# MKL05Z4 register map
Vendor: Freescale Semiconductor, Inc.; File version: 1.6
CPU: CM0PLUS r0p0, little endian, no MPU, no FPU, 0x2 interrupt priority bits, 0x0 interrupts
Registers are 32-bit, read-write, reset 0x0 unless marked. A register's access mark holds for its fields unless they carry their own. Offsets are from the block's base; [hi:lo] are bit positions; {n}, {i} and the like mark numbered series.

## GPIOA — General Purpose Input/Output
Base 0x400FF000; register names take the prefix GPIOA_
0x00 PDOR — Port Data Output Register
  [31:0] PDO — Port Data Output
    0=Logic level 0 is driven on pin, provided pin is configured for general-purpose output; 1=Logic level 1 is driven on pin, provided pin is configured for general-purpose output
0x04 PSOR wo — Port Set Output Register
  [31:0] PTSO — Port Set Output
    0=Corresponding bit in PDORn does not change; 1=Corresponding bit in PDORn is set to logic 1
0x08 PCOR wo — Port Clear Output Register
  [31:0] PTCO — Port Clear Output
    0=Corresponding bit in PDORn does not change; 1=Corresponding bit in PDORn is cleared to logic 0
0x0C PTOR wo — Port Toggle Output Register
  [31:0] PTTO — Port Toggle Output
    0=Corresponding bit in PDORn does not change; 1=Corresponding bit in PDORn is set to the inverse of its existing logic state
0x10 PDIR ro — Port Data Input Register
  [31:0] PDI — Port Data Input
    0=Pin logic level is logic 0, or is not configured for use by digital function; 1=Pin logic level is logic 1
0x14 PDDR — Port Data Direction Register
  [31:0] PDD — Port Data Direction
    0=Pin is configured as general-purpose input, for the GPIO function; 1=Pin is configured as general-purpose output, for the GPIO function

## GPIOB — General Purpose Input/Output
Base 0x400FF040; register names take the prefix GPIOB_
Registers as GPIOA.

## FGPIOA — General Purpose Input/Output
Base 0xF80FF000; register names take the prefix FGPIOA_
Registers as GPIOA.

## FGPIOB — General Purpose Input/Output
Base 0xF80FF040; register names take the prefix FGPIOB_
Registers as GPIOA.

## MTB — Micro Trace Buffer
Base 0xF0000000; register names take the prefix MTB_
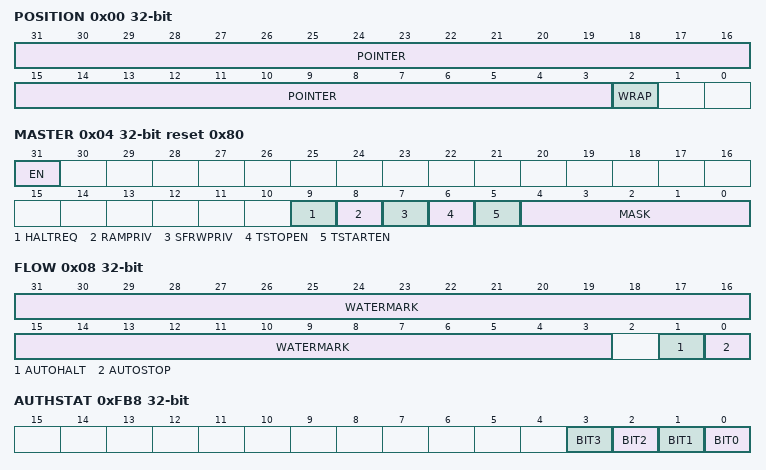
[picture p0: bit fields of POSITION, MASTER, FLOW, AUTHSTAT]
0x00 POSITION (reset mask 0x3) — MTB Position Register
  [31:3] POINTER — Trace Packet Address Pointer
  [2] WRAP
0x04 MASTER reset 0x80 — MTB Master Register
  [31] EN — Main trace enable bit
  [9] HALTREQ — Halt request bit
  [8] RAMPRIV — RAM privilege bit
  [7] SFRWPRIV — Special Function Register Write Privilege bit
  [6] TSTOPEN — Trace stop input enable
  [5] TSTARTEN — Trace start input enable
  [4:0] MASK
0x08 FLOW (reset mask 0x4) — MTB Flow Register
  [31:3] WATERMARK — WATERMARK value
  [1] AUTOHALT
  [0] AUTOSTOP
0x0C BASE ro reset not defined — MTB Base Register
  [31:0] BASEADDR
0xF00 MODECTRL ro — Integration Mode Control Register
0xFA0 TAGSET ro — Claim TAG Set Register
0xFA4 TAGCLEAR ro — Claim TAG Clear Register
0xFB0 LOCKACCESS ro
0xFB4 LOCKSTAT ro — Lock Status Register
0xFB8 AUTHSTAT ro — Authentication Status Register
  [n] BIT{n} (n=0..3)
0xFBC DEVICEARCH ro reset 0x47700A31 — Device Architecture Register
0xFC8 DEVICECFG ro — Device Configuration Register
0xFCC DEVICETYPID ro reset 0x31 — Device Type Identifier Register
{0xFC0+4i} PERIPHID{i} ro reset not defined (i=4..7) — Peripheral ID Register
  [31:0] PERIPHID
{0xFE0+4i} PERIPHID{i} ro reset not defined (i=0..3) — Peripheral ID Register
  [31:0] PERIPHID
{0xFF0+4i} COMPID{i} ro reset not defined (i=0..3) — Component ID Register
  [31:0] COMPID — Component ID

## ROM — System ROM
Base 0xF0002000; register names take the prefix ROM_
Registers as MTB, without POSITION, MASTER, FLOW, BASE, MODECTRL, TAGSET, TAGCLEAR, LOCKACCESS, LOCKSTAT, AUTHSTAT, DEVICEARCH, DEVICECFG, DEVICETYPID; these are added or differ:
{0x0+4i} ENTRY{i} ro reset not defined (i=0..2) — Entry
  [31:0] ENTRY
0x0C TABLEMARK ro — End of Table Marker Register
  [31:0] MARK
0xFCC SYSACCESS ro reset 0x1 — System Access Register
